# ATSAM4E16E device description
Architecture: CORTEX-M4; Family: SAM4; Series: SAM4E
Registers are 32-bit, read-write, no defined reset value unless marked. A register's access mark holds for its fields unless they carry their own. Offsets are from the block's base; [hi:lo] are bit positions; {n}, {i} and the like mark numbered series.

## PWM — Pulse Width Modulation Controller
Instances: PWM 0x40000000
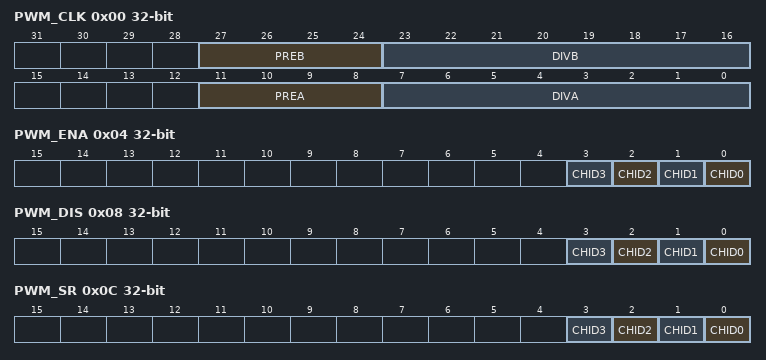
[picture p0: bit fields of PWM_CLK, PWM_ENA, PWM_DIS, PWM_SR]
0x00 PWM_CLK — PWM Clock Register
  [27:24] PREB — CLKA, CLKB Source Clock Selection
  [23:16] DIVB — CLKA, CLKB Divide Factor
  [11:8] PREA — CLKA, CLKB Source Clock Selection
  [7:0] DIVA — CLKA, CLKB Divide Factor
0x04 PWM_ENA wo — PWM Enable Register
  [n] CHID{n} (n=0..3) — Channel ID
0x08 PWM_DIS wo — PWM Disable Register
  [n] CHID{n} (n=0..3) — Channel ID
0x0C PWM_SR ro — PWM Status Register
  [n] CHID{n} (n=0..3) — Channel ID
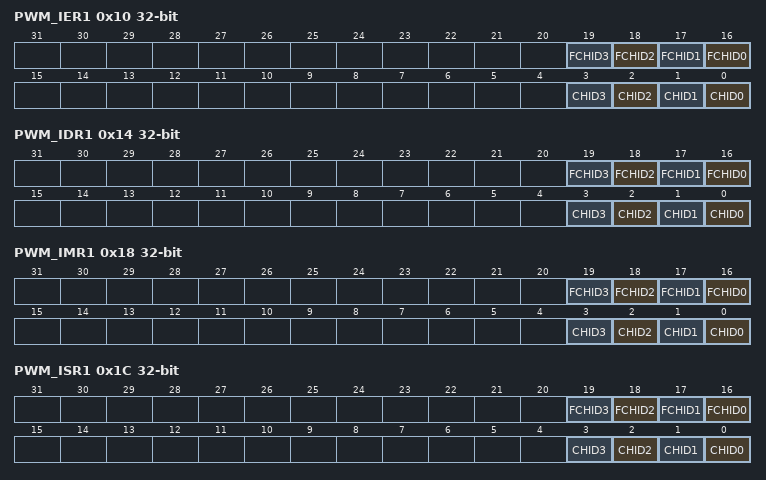
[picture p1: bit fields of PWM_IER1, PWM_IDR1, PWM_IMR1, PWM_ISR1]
0x10 PWM_IER1 wo — PWM Interrupt Enable Register 1
  [n+16] FCHID{n} (n=0..3) — Fault Protection Trigger on Channel {n} Interrupt Enable
  [n] CHID{n} (n=0..3) — Counter Event on Channel {n} Interrupt Enable
0x14 PWM_IDR1 wo — PWM Interrupt Disable Register 1
  [n+16] FCHID{n} (n=0..3) — Fault Protection Trigger on Channel {n} Interrupt Disable
  [n] CHID{n} (n=0..3) — Counter Event on Channel {n} Interrupt Disable
0x18 PWM_IMR1 ro — PWM Interrupt Mask Register 1
  [n+16] FCHID{n} (n=0..3) — Fault Protection Trigger on Channel {n} Interrupt Mask
  [n] CHID{n} (n=0..3) — Counter Event on Channel {n} Interrupt Mask
0x1C PWM_ISR1 ro — PWM Interrupt Status Register 1
  [n+16] FCHID{n} (n=0..3) — Fault Protection Trigger on Channel {n}
  [n] CHID{n} (n=0..3) — Counter Event on Channel {n}
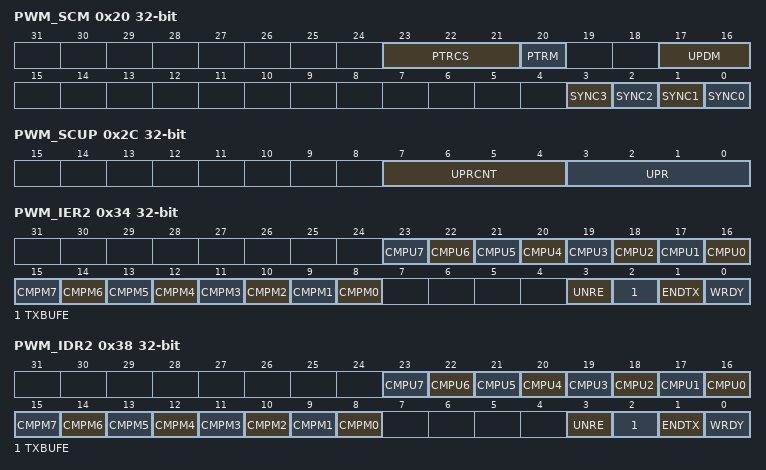
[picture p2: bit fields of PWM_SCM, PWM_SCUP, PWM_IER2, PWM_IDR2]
0x20 PWM_SCM — PWM Sync Channels Mode Register
  [23:21] PTRCS — PDC Transfer Request Comparison Selection
  [20] PTRM — PDC Transfer Request Mode
  [17:16] UPDM — Synchronous Channels Update Mode
    0=MODE0 (Manual write of double buffer registers and manual update of synchronous channels); 1=MODE1 (Manual write of double buffer registers and automatic update of synchronous channels); 2=MODE2 (Automatic write of duty-cycle update registers by the PDC and automatic update of synchronous channels)
  [n] SYNC{n} (n=0..3) — Synchronous Channel {n}
0x28 PWM_SCUC — PWM Sync Channels Update Control Register
  [0] UPDULOCK — Synchronous Channels Update Unlock
0x2C PWM_SCUP — PWM Sync Channels Update Period Register
  [7:4] UPRCNT — Update Period Counter
  [3:0] UPR — Update Period
0x30 PWM_SCUPUPD wo — PWM Sync Channels Update Period Update Register
  [3:0] UPRUPD — Update Period Update
0x34 PWM_IER2 wo — PWM Interrupt Enable Register 2
  [n+16] CMPU{n} (n=0..7) — Comparison {n} Update Interrupt Enable
  [n+8] CMPM{n} (n=0..7) — Comparison {n} Match Interrupt Enable
  [3] UNRE — Synchronous Channels Update Underrun Error Interrupt Enable
  [2] TXBUFE — PDC TX Buffer Empty Interrupt Enable
  [1] ENDTX — PDC End of TX Buffer Interrupt Enable
  [0] WRDY — Write Ready for Synchronous Channels Update Interrupt Enable
0x38 PWM_IDR2 wo — PWM Interrupt Disable Register 2
  [n+16] CMPU{n} (n=0..7) — Comparison {n} Update Interrupt Disable
  [n+8] CMPM{n} (n=0..7) — Comparison {n} Match Interrupt Disable
  [3] UNRE — Synchronous Channels Update Underrun Error Interrupt Disable
  [2] TXBUFE — PDC TX Buffer Empty Interrupt Disable
  [1] ENDTX — PDC End of TX Buffer Interrupt Disable
  [0] WRDY — Write Ready for Synchronous Channels Update Interrupt Disable
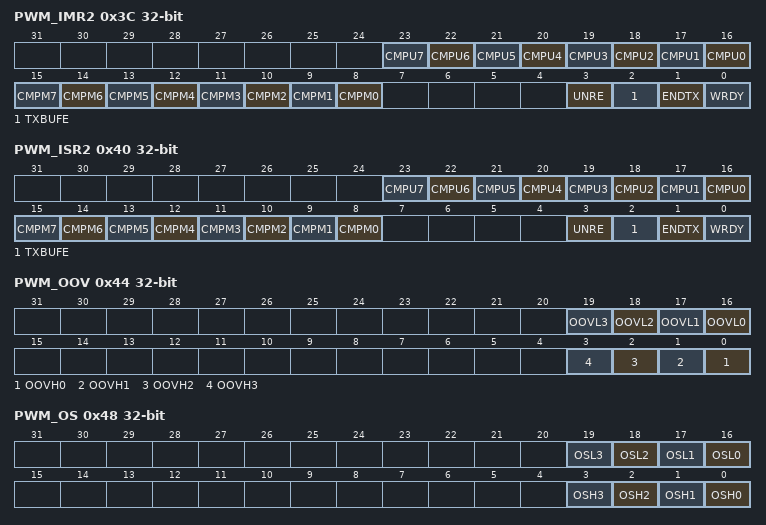
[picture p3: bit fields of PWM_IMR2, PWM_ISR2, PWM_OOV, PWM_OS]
0x3C PWM_IMR2 ro — PWM Interrupt Mask Register 2
  [n+16] CMPU{n} (n=0..7) — Comparison {n} Update Interrupt Mask
  [n+8] CMPM{n} (n=0..7) — Comparison {n} Match Interrupt Mask
  [3] UNRE — Synchronous Channels Update Underrun Error Interrupt Mask
  [2] TXBUFE — PDC TX Buffer Empty Interrupt Mask
  [1] ENDTX — PDC End of TX Buffer Interrupt Mask
  [0] WRDY — Write Ready for Synchronous Channels Update Interrupt Mask
0x40 PWM_ISR2 ro — PWM Interrupt Status Register 2
  [n+16] CMPU{n} (n=0..7) — Comparison {n} Update
  [n+8] CMPM{n} (n=0..7) — Comparison {n} Match
  [3] UNRE — Synchronous Channels Update Underrun Error
  [2] TXBUFE — PDC TX Buffer Empty
  [1] ENDTX — PDC End of TX Buffer
  [0] WRDY — Write Ready for Synchronous Channels Update
0x44 PWM_OOV — PWM Output Override Value Register
  [n+16] OOVL{n} (n=0..3) — Output Override Value for PWML output of the channel {n}
  [n] OOVH{n} (n=0..3) — Output Override Value for PWMH output of the channel {n}
0x48 PWM_OS — PWM Output Selection Register
  [n+16] OSL{n} (n=0..3) — Output Selection for PWML output of the channel {n}
  [n] OSH{n} (n=0..3) — Output Selection for PWMH output of the channel {n}
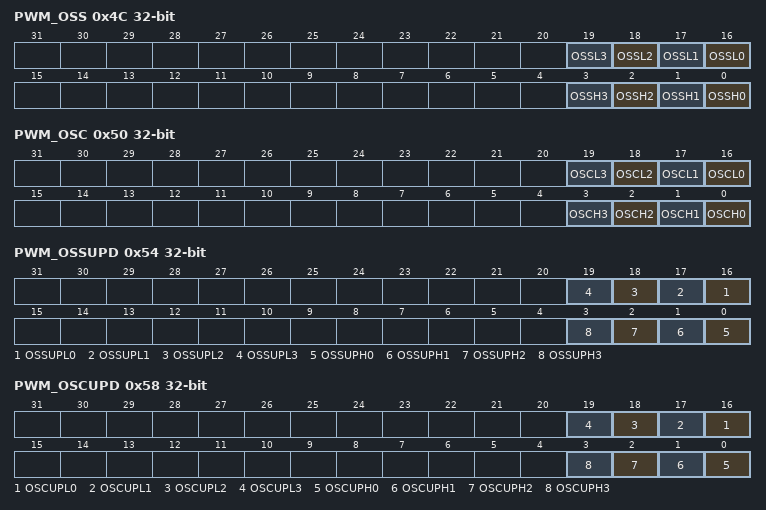
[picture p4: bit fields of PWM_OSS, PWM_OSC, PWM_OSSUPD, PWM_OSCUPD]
0x4C PWM_OSS wo — PWM Output Selection Set Register
  [n+16] OSSL{n} (n=0..3) — Output Selection Set for PWML output of the channel {n}
  [n] OSSH{n} (n=0..3) — Output Selection Set for PWMH output of the channel {n}
0x50 PWM_OSC wo — PWM Output Selection Clear Register
  [n+16] OSCL{n} (n=0..3) — Output Selection Clear for PWML output of the channel {n}
  [n] OSCH{n} (n=0..3) — Output Selection Clear for PWMH output of the channel {n}
0x54 PWM_OSSUPD wo — PWM Output Selection Set Update Register
  [n+16] OSSUPL{n} (n=0..3) — Output Selection Set for PWML output of the channel {n}
  [n] OSSUPH{n} (n=0..3) — Output Selection Set for PWMH output of the channel {n}
0x58 PWM_OSCUPD wo — PWM Output Selection Clear Update Register
  [n+16] OSCUPL{n} (n=0..3) — Output Selection Clear for PWML output of the channel {n}
  [n] OSCUPH{n} (n=0..3) — Output Selection Clear for PWMH output of the channel {n}
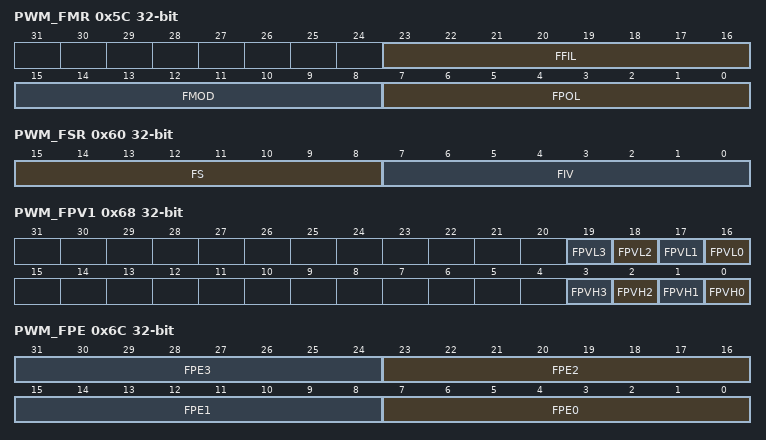
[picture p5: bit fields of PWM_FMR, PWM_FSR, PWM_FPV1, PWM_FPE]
0x5C PWM_FMR — PWM Fault Mode Register
  [23:16] FFIL — Fault Filtering (fault input bit varies from 0 to 7)
  [15:8] FMOD — Fault Activation Mode (fault input bit varies from 0 to 7)
  [7:0] FPOL — Fault Polarity (fault input bit varies from 0 to 7)
0x60 PWM_FSR ro — PWM Fault Status Register
  [15:8] FS — Fault Status (fault input bit varies from 0 to 7)
  [7:0] FIV — Fault Input Value (fault input bit varies from 0 to 7)
0x64 PWM_FCR wo — PWM Fault Clear Register
  [7:0] FCLR — Fault Clear (fault input bit varies from 0 to 7)
0x68 PWM_FPV1 — PWM Fault Protection Value Register 1
  [n+16] FPVL{n} (n=0..3) — Fault Protection Value for PWML output on channel {n}
  [n] FPVH{n} (n=0..3) — Fault Protection Value for PWMH output on channel {n}
0x6C PWM_FPE — PWM Fault Protection Enable Register
  [8n+7:8n] FPE{n} (n=0..3) — Fault Protection Enable for channel {n} (fault input bit varies from 0 to 7)
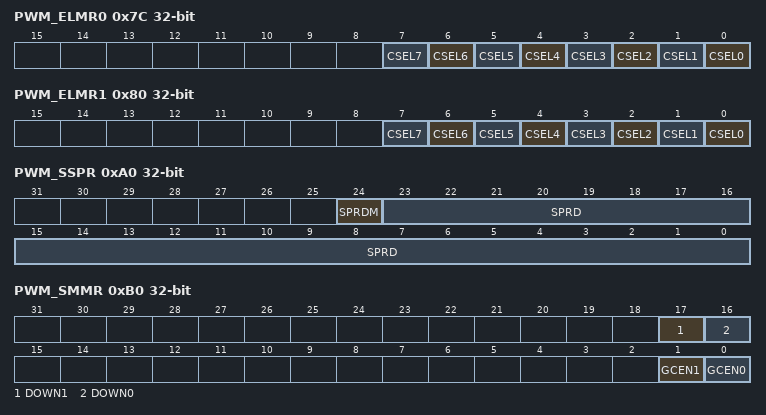
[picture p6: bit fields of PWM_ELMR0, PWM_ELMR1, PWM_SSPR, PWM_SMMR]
0x7C PWM_ELMR0 — PWM Event Line 0 Mode Register 0
  [n] CSEL{n} (n=0..7) — Comparison {n} Selection
0x80 PWM_ELMR1 — PWM Event Line 0 Mode Register 1
  [n] CSEL{n} (n=0..7) — Comparison {n} Selection
0xA0 PWM_SSPR — PWM Spread Spectrum Register
  [24] SPRDM — Spread Spectrum Counter Mode
  [23:0] SPRD — Spread Spectrum Limit Value
0xA4 PWM_SSPUP wo — PWM Spread Spectrum Update Register
  [23:0] SPRDUP — Spread Spectrum Limit Value Update
0xB0 PWM_SMMR — PWM Stepper Motor Mode Register
  [17] DOWN1 — DOWN Count
  [16] DOWN0 — DOWN Count
  [1] GCEN1 — Gray Count ENable
  [0] GCEN0 — Gray Count ENable
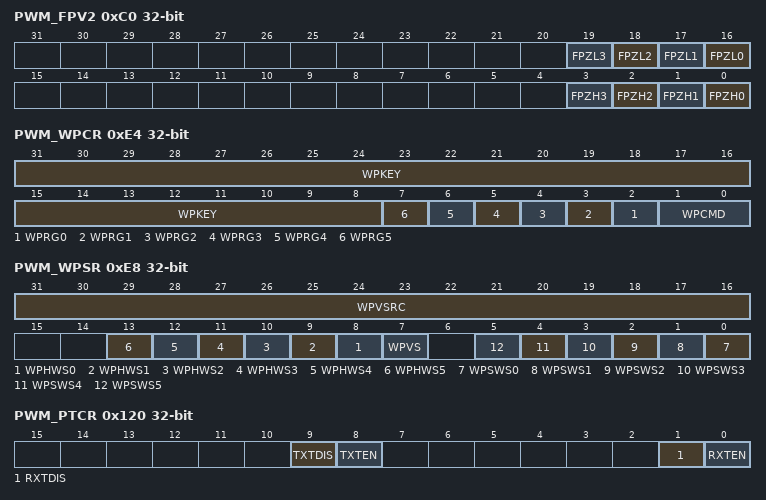
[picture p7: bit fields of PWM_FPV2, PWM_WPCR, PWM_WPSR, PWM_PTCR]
0xC0 PWM_FPV2 — PWM Fault Protection Value 2 Register
  [n+16] FPZL{n} (n=0..3) — Fault Protection to Hi-Z for PWML output on channel {n}
  [n] FPZH{n} (n=0..3) — Fault Protection to Hi-Z for PWMH output on channel {n}
0xE4 PWM_WPCR wo — PWM Write Protect Control Register
  [31:8] WPKEY — Write Protect Key
  [n+2] WPRG{n} (n=0..5) — Write Protect Register Group {n}
  [1:0] WPCMD — Write Protect Command
0xE8 PWM_WPSR ro — PWM Write Protect Status Register
  [31:16] WPVSRC — Write Protect Violation Source
  [n+8] WPHWS{n} (n=0..5) — Write Protect HW Status
  [7] WPVS — Write Protect Violation Status
  [n] WPSWS{n} (n=0..5) — Write Protect SW Status
0x108 PWM_TPR — Transmit Pointer Register
  [31:0] TXPTR — Transmit Counter Register
0x10C PWM_TCR — Transmit Counter Register
  [15:0] TXCTR
0x118 PWM_TNPR — Transmit Next Pointer Register
  [31:0] TXNPTR — Transmit Next Pointer
0x11C PWM_TNCR — Transmit Next Counter Register
  [15:0] TXNCTR — Transmit Counter Next
0x120 PWM_PTCR wo — Transfer Control Register
  [9] TXTDIS — Transmitter Transfer Disable
  [8] TXTEN — Transmitter Transfer Enable
  [1] RXTDIS — Receiver Transfer Disable
  [0] RXTEN — Receiver Transfer Enable
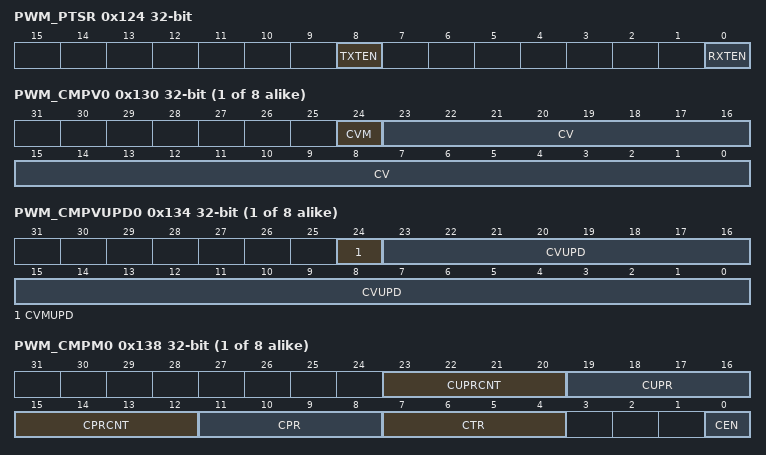
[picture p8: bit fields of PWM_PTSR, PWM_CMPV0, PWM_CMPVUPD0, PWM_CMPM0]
0x124 PWM_PTSR ro — Transfer Status Register
  [8] TXTEN — Transmitter Transfer Enable
  [0] RXTEN — Receiver Transfer Enable
{0x130+0x10*i} PWM_CMPV{i} (i=0..7) — PWM Comparison {i} Value Register
  [24] CVM — Comparison x Value Mode
  [23:0] CV — Comparison x Value
{0x134+0x10*i} PWM_CMPVUPD{i} wo (i=0..7) — PWM Comparison {i} Value Update Register
  [24] CVMUPD — Comparison x Value Mode Update
  [23:0] CVUPD — Comparison x Value Update
{0x138+0x10*i} PWM_CMPM{i} (i=0..7) — PWM Comparison {i} Mode Register
  [23:20] CUPRCNT — Comparison x Update Period Counter
  [19:16] CUPR — Comparison x Update Period
  [15:12] CPRCNT — Comparison x Period Counter
  [11:8] CPR — Comparison x Period
  [7:4] CTR — Comparison x Trigger
  [0] CEN — Comparison x Enable
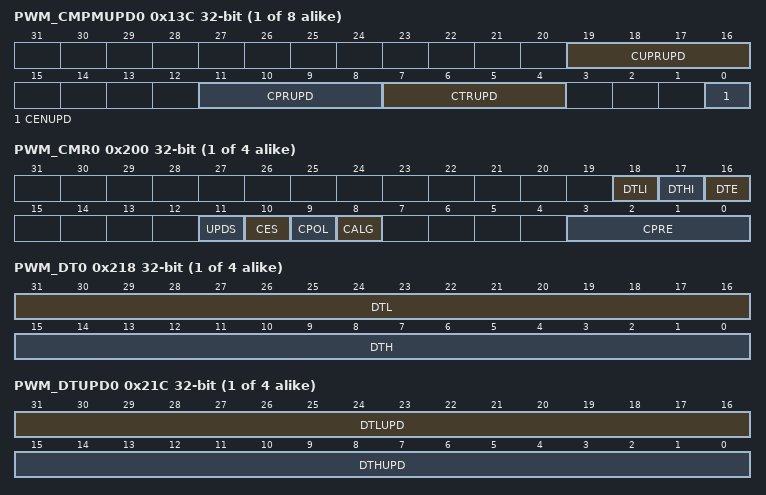
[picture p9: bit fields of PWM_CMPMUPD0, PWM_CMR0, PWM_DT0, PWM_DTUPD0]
{0x13C+0x10*i} PWM_CMPMUPD{i} wo (i=0..7) — PWM Comparison {i} Mode Update Register
  [19:16] CUPRUPD — Comparison x Update Period Update
  [11:8] CPRUPD — Comparison x Period Update
  [7:4] CTRUPD — Comparison x Trigger Update
  [0] CENUPD — Comparison x Enable Update
{0x200+0x20*i} PWM_CMR{i} (i=0..3) — PWM Channel Mode Register (ch_num = {i})
  [18] DTLI — Dead-Time PWMLx Output Inverted
  [17] DTHI — Dead-Time PWMHx Output Inverted
  [16] DTE — Dead-Time Generator Enable
  [11] UPDS — Update Selection
  [10] CES — Counter Event Selection
  [9] CPOL — Channel Polarity
  [8] CALG — Channel Alignment
  [3:0] CPRE — Channel Pre-scaler
    0=MCK (Master clock); 1=MCK_DIV_2 (Master clock/2); 2=MCK_DIV_4 (Master clock/4); 3=MCK_DIV_8 (Master clock/8); 4=MCK_DIV_16 (Master clock/16); 5=MCK_DIV_32 (Master clock/32); 6=MCK_DIV_64 (Master clock/64); 7=MCK_DIV_128 (Master clock/128); 8=MCK_DIV_256 (Master clock/256); 9=MCK_DIV_512 (Master clock/512); 10=MCK_DIV_1024 (Master clock/1024); 11=CLKA (Clock A); 12=CLKB (Clock B)
{0x204+0x20*i} PWM_CDTY{i} (i=0..3) — PWM Channel Duty Cycle Register (ch_num = {i})
  [23:0] CDTY — Channel Duty-Cycle
{0x208+0x20*i} PWM_CDTYUPD{i} wo (i=0..3) — PWM Channel Duty Cycle Update Register (ch_num = {i})
  [23:0] CDTYUPD — Channel Duty-Cycle Update
{0x20C+0x20*i} PWM_CPRD{i} (i=0..3) — PWM Channel Period Register (ch_num = {i})
  [23:0] CPRD — Channel Period
{0x210+0x20*i} PWM_CPRDUPD{i} wo (i=0..3) — PWM Channel Period Update Register (ch_num = {i})
  [23:0] CPRDUPD — Channel Period Update
{0x214+0x20*i} PWM_CCNT{i} ro (i=0..3) — PWM Channel Counter Register (ch_num = {i})
  [23:0] CNT — Channel Counter Register
{0x218+0x20*i} PWM_DT{i} (i=0..3) — PWM Channel Dead Time Register (ch_num = {i})
  [31:16] DTL — Dead-Time Value for PWMLx Output
  [15:0] DTH — Dead-Time Value for PWMHx Output
{0x21C+0x20*i} PWM_DTUPD{i} wo (i=0..3) — PWM Channel Dead Time Update Register (ch_num = {i})
  [31:16] DTLUPD — Dead-Time Value Update for PWMLx Output
  [15:0] DTHUPD — Dead-Time Value Update for PWMHx Output
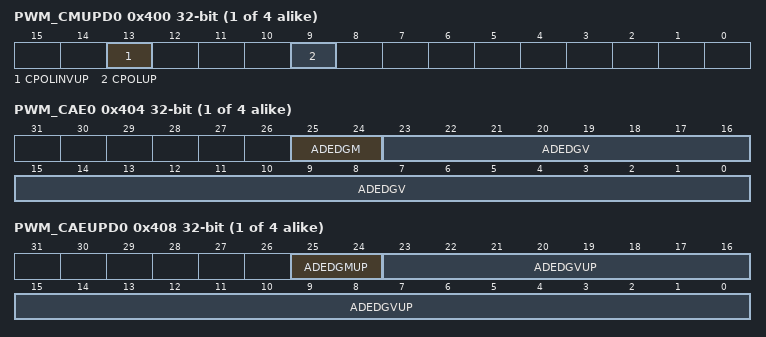
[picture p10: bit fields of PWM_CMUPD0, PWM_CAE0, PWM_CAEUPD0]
{0x400+0x20*i} PWM_CMUPD{i} wo (i=0..3) — PWM Channel Mode Update Register (ch_num = {i})
  [13] CPOLINVUP — Channel Polarity Inversion Update
  [9] CPOLUP — Channel Polarity Update
{0x404+0x20*i} PWM_CAE{i} (i=0..3) — PWM Channel Additional Edge Register (ch_num = {i})
  [25:24] ADEDGM — Channel Additional Edge Mode
    0=INC (The additional edge of the channel x output waveform occurs when CCNTx reaches ADEDGV and the counter of the channel x is incrementing.); 1=DEC (The additional edge of the channel x output waveform occurs when CCNTx reaches ADEDGV and the counter of the channel x is incrementing.); 2=BOTH (The additional edge of the channel x output waveform occurs when CCNTx reaches ADEDGV, whether the counter is incrementing or not.)
  [23:0] ADEDGV — Channel Additional Edge Value
{0x408+0x20*i} PWM_CAEUPD{i} wo (i=0..3) — PWM Channel Additional Edge Update Register (ch_num = {i})
  [25:24] ADEDGMUP — Channel Additional Edge Mode Update
    0=INC (The additional edge of the channel x output waveform occurs when CCNTx reaches ADEDGVUP and the counter of the channel x is incrementing.); 1=DEC (The additional edge of the channel x output waveform occurs when CCNTx reaches ADEDGVUP and the counter of the channel x is incrementing.); 2=BOTH (The additional edge of the channel x output waveform occurs when CCNTx reaches ADEDGVUP, whether the counter is incrementing or not.)
  [23:0] ADEDGVUP — Channel Additional Edge Value Update
